# RCSS_MCASP register map
Vendor: Texas Instruments
Peripheral module from a debugger description file (folder am273).
Registers are 32-bit, read-write, no defined reset value unless marked. A register's access mark holds for its fields unless they carry their own. Offsets are as the file gives them; lines under a group give offsets from that group; [hi:lo] are bit positions; {n}, {i} and the like mark numbered series; 'fields as' and 'values as' point back to an identical list; <NAME> marks a mode.

## RCSS_MCASP (part 1 of 2)
0x00 PID ro — The revision identification register (PID) contains identification data for the peripheral.
  [31:0] ? — Identifies revision of peripheral.
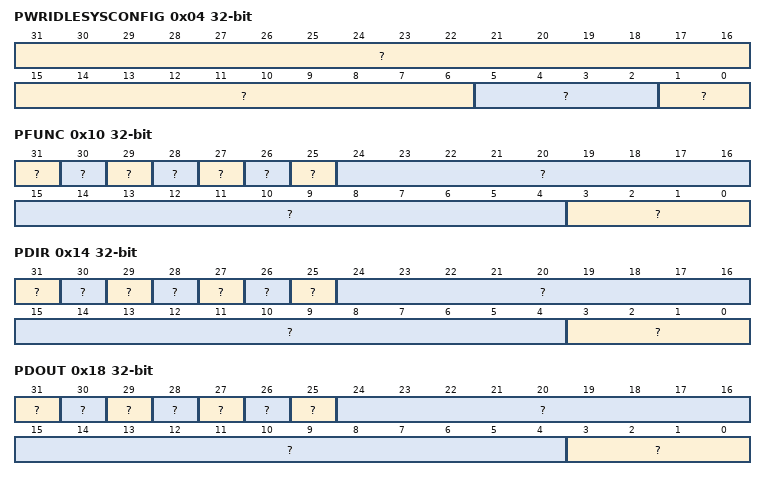
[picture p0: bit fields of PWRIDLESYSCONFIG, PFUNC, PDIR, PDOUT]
0x04 PWRIDLESYSCONFIG access per field
  [31:6] ? ro
  [5:2] ? rw — Reserved for future programming.
  [1:0] ? rw — Power management Configuration of the local target state management mode. By definition, target can handle read/write transaction as long as it is out of IDLE state.
    0=en_1_0x0 (Force-idle mode: local target's idle state follows (acknowledges) the system's idle requests unconditionally, i.e. regardless of the IP module's internal requirements. Backup mode, for debug only.); 1=en_2_0x1 (No-idle mode: local target never enters idle state. Backup mode, for debug only.); 2=en_3_0x2 (Smart-idle mode: local target's idle state eventually follows (acknowledges) the system's idle requests, depending on the IP module's internal requirements. IP module shall not generate (IRQ- or DMA-request-related) wakeup events.); 3=en_4_0x3 (Reserved.)
0x10 PFUNC access per field — The pin function register (PFUNC) specifies the function of AXRn, ACLKX, AHCLKX, AFSX, ACLKR, AHCLKR, and AFSR pins as either a McASP pin or a general-purpose input/output (GPIO) pin. CAUTION: Writing a value other than 0 to reserved bits in this register may cause improper device operation.
  [31] ? rw — Determines if AFSR pin functions as McASP or GPIO.
    0=en_1_0x0 (Pin functions as McASP pin.); 1=en_2_0x1 (Pin functions as GPIO pin.)
  [30] ? rw — Determines if AHCLKR pin functions as McASP or GPIO.
    values as ?
  [29] ? rw — Determines if ACLKR pin functions as McASP or GPIO.
    values as ?
  [28] ? rw — Determines if AFSX pin functions as McASP or GPIO.
    values as ?
  [27] ? rw — Determines if AHCLKX pin functions as McASP or GPIO.
    values as ?
  [26] ? rw — Determines if ACLKX pin functions as McASP or GPIO.
    values as ?
  [25] ? rw — Determines if AMUTE pin functions as McASP or GPIO.
    values as ?
  [24:4] ? ro
  [3:0] ? rw — Determines if AXRn pin functions as McASP or GPIO.
    values as ?
0x14 PDIR access per field — The pin direction register (PDIR) specifies the direction of AXRn, ACLKX, AHCLKX, AFSX, ACLKR, AHCLKR, and AFSR pins as either an input or an output pin. Regardless of the pin function register (PFUNC) setting, each PDIR bit must be set to 1 for the specified pin to be enabled as an output and each PDIR bit must be cleared to 0 for the specified pin to be an input. For example, if the McASP is configured to use an internally-generated bit clock and the clock is to be driven out to the system, the PFUNC bit must be cleared to 0 (McASP function) and the PDIR bit must be set to 1 (an output). When AXRn is configured to transmit, the PFUNC bit must be cleared to 0 (McASP function) and the PDIR bit must be set to 1 (an output). Similarly, when AXRn is configured to receive, the PFUNC bit must be cleared to 0 (McASP function) and the PDIR bit must be cleared to 0 (an input). CAUTION: Writing a value other than 0 to reserved bits in this register may cause improper device operation.
  [31] ? rw — Determines if AFSR pin functions as an input or output.
    0=en_1_0x0 (Pin functions as input.); 1=en_2_0x1 (Pin functions as output.)
  [30] ? rw — Determines if AHCLKR pin functions as an input or output.
    values as ?
  [29] ? rw — Determines if ACLKR pin functions as an input or output.
    values as ?
  [28] ? rw — Determines if AFSX pin functions as an input or output.
    values as ?
  [27] ? rw — Determines if AHCLKX pin functions as an input or output.
    values as ?
  [26] ? rw — Determines if ACLKX pin functions as an input or output.
    values as ?
  [25] ? rw — Determines if AMUTE pin functions as an input or output.
    values as ?
  [24:4] ? ro
  [3:0] ? rw — Determines if AXRn pin functions as an input or output.
    values as ?
0x18 PDOUT access per field — The pin data output register (PDOUT) holds a value for data out at all times, and may be read back at all times. The value held by PDOUT is not affected by writing to PDIR and PFUNC. However, the data value in PDOUT is driven out onto the McASP pin only if the corresponding bit in PFUNC is set to 1 (GPIO function) and the corresponding bit in PDIR is set to 1 (output). When reading data, returns the corresponding bit value in PDOUT[n], does not return input from I/O pin; when writing data, writes to the corresponding PDOUT[n] bit. PDOUT has these aliases or alternate addresses: PDSET When written to at this address, writing a 1 to a bit in PDSET sets the corresponding bit in PDOUT to 1; writing a 0 has no effect and keeps the bits in PDOUT unchanged. PDCLR When written to at this address, writing a 1 to a bit in PDCLR clears the corresponding bit in PDOUT to 0; writing a 0 has no effect and keeps the bits in PDOUT unchanged. There is only one set of data out bits, PDOUT[31-0]. The other registers, PDSET and PDCLR, are just different addresses for the same control bits, with different behaviors during writes. CAUTION: Writing a value other than 0 to reserved bits in this register may cause improper device operation.
  [31] ? rw — Determines drive on AFSR output pin when the corresponding PFUNC[31] and PDIR[31] bits are set to 1.
    0=en_1_0x0 (Pin drives low.); 1=en_2_0x1 (Pin drives high.)
  [30] ? rw — Determines drive on AHCLKR output pin when the corresponding PFUNC[30] and PDIR[30] bits are set to 1.
    0=en_1_0x0 (Pin drives low.); 1=en_2_0x1 (Pin drives high.)
  [29] ? rw — Determines drive on ACLKR output pin when the corresponding PFUNC[29] and PDIR[29] bits are set to 1.
    0=en_1_0x0 (Pin drives low.); 1=en_2_0x1 (Pin drives high.)
  [28] ? rw — Determines drive on AFSX output pin when the corresponding PFUNC[28] and PDIR[28] bits are set to 1.
    0=en_1_0x0 (Pin drives low.); 1=en_2_0x1 (Pin drives high.)
  [27] ? rw — Determines drive on AHCLKX output pin when the corresponding PFUNC[27] and PDIR[27] bits are set to 1.
    0=en_1_0x0 (Pin drives low.); 1=en_2_0x1 (Pin drives high.)
  [26] ? rw — Determines drive on ACLKX output pin when the corresponding PFUNC[26] and PDIR[26] bits are set to 1.
    0=en_1_0x0 (Pin drives low.); 1=en_2_0x1 (Pin drives high.)
  [25] ? rw — Determines drive on AMUTE output pin when the corresponding PFUNC[25] and PDIR[25] bits are set to 1.
    0=en_1_0x0 (Pin drives low.); 1=en_2_0x1 (Pin drives high.)
  [24:4] ? ro
  [3:0] ? rw — Determines drive on AXR[n] output pin when the corresponding PFUNC[n] and PDIR[n] bits are set to 1.
    0=en_1_0x0 (Pin drives low.); 1=en_2_0x1 (Pin drives high.)
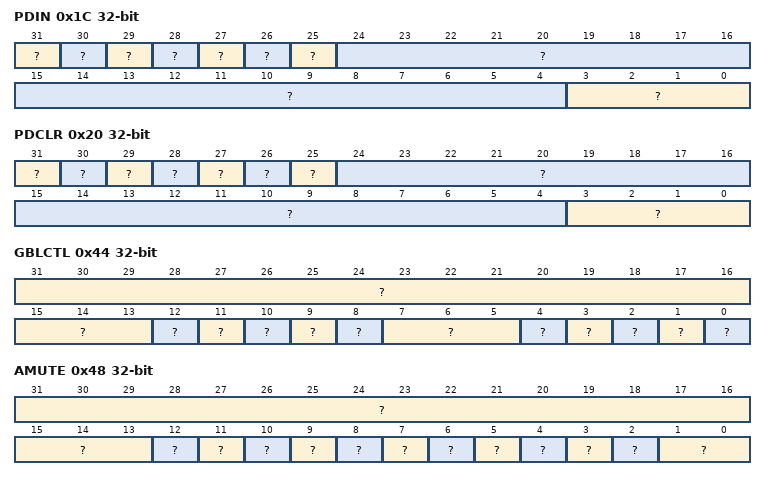
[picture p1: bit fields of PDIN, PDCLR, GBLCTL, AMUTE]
0x1C PDIN access per field — The pin data input register (PDIN) holds the I/O pin state of each of the McASP pins. PDIN allows the actual value of the pin to be read, regardless of the state of PFUNC and PDIR. The value after reset for registers 1 through 15 and 24 through 31 depends on how the pins are being driven. CAUTION: Writing a value other than 0 to reserved bits in this register may cause improper device operation.
  [31] ? rw — Logic level on AFSR pin.
    0=en_1_0x0 (Pin is logic low.); 1=en_2_0x1 (Pin is logic high.)
  [30] ? rw — Logic level on AHCLKR pin.
    values as ?
  [29] ? rw — Logic level on ACLKR pin.
    values as ?
  [28] ? rw — Logic level on AFSX pin.
    values as ?
  [27] ? rw — Logic level on AHCLKX pin.
    values as ?
  [26] ? rw — Logic level on ACLKX pin.
    values as ?
  [25] ? rw — Logic level on AMUTE pin.
    values as ?
  [24:4] ? ro
  [3:0] ? rw — Logic level on AXR[n] pin.
    values as ?
0x20 PDCLR access per field — The pin data clear register (PDCLR) is an alias of the pin data output register (PDOUT) for writes only. Writing a 1 to the PDCLR bit clears the corresponding bit in PDOUT and, if PFUNC = 1 (GPIO function) and PDIR = 1 (output), drives a logic low on the pin. PDCLR is useful for a multitasking system because it allows you to clear to a logic low only the desired pin(s) within a system without affecting other I/O pins controlled by the same McASP. CAUTION: Writing a value other than 0 to reserved bits in this register may cause improper device operation.
  [31] ? rw — Allows the corresponding AFSR bit in PDOUT to be cleared to a logic low without affecting other I/O pins controlled by the same port.
    0=en_1_0x0 (No effect.); 1=en_2_0x1 (PDOUT[31] bit is cleared to 0.)
  [30] ? rw — Allows the corresponding AHCLKR bit in PDOUT to be cleared to a logic low without affecting other I/O pins controlled by the same port.
    0=en_1_0x0 (No effect.); 1=en_2_0x1 (PDOUT[30] bit is cleared to 0.)
  [29] ? rw — Allows the corresponding ACLKR bit in PDOUT to be cleared to a logic low without affecting other I/O pins controlled by the same port.
    0=en_1_0x0 (No effect.); 1=en_2_0x1 (PDOUT[29] bit is cleared to 0.)
  [28] ? rw — Allows the corresponding AFSX bit in PDOUT to be cleared to a logic low without affecting other I/O pins controlled by the same port.
    0=en_1_0x0 (No effect.); 1=en_2_0x1 (PDOUT[28] bit is cleared to 0.)
  [27] ? rw — Allows the corresponding AHCLKX bit in PDOUT to be cleared to a logic low without affecting other I/O pins controlled by the same port.
    0=en_1_0x0 (No effect.); 1=en_2_0x1 (PDOUT[27] bit is cleared to 0.)
  [26] ? rw — Allows the corresponding ACLKX bit in PDOUT to be cleared to a logic low without affecting other I/O pins controlled by the same port.
    0=en_1_0x0 (No effect.); 1=en_2_0x1 (PDOUT[26] bit is cleared to 0.)
  [25] ? rw — Allows the corresponding AMUTE bit in PDOUT to be cleared to a logic low without affecting other I/O pins controlled by the same port.
    0=en_1_0x0 (No effect.); 1=en_2_0x1 (PDOUT[25] bit is cleared to 0.)
  [24:4] ? ro
  [3:0] ? rw — Allows the corresponding AXR[n] bit in PDOUT to be cleared to a logic low without affecting other I/O pins controlled by the same port.
    0=en_1_0x0 (No effect.); 1=en_2_0x1 (PDOUT[n] bit is cleared to 0.)
0x44 GBLCTL access per field — The global control register (GBLCTL) provides initialization of the transmit and receive sections. The bit fields in GBLCTL are synchronized and latched by the corresponding clocks (ACLKX for bits 12-8 and ACLKR for bits 4-0). Before GBLCTL is programmed, you must ensure that serial clocks are running. If the corresponding external serial clocks, ACLKX and ACLKR, are not yet running, you should select the internal serial clock source in AHCLKXCTL, AHCLKRCTL, ACLKXCTL, and ACLKRCTL before GBLCTL is programmed. Also, after programming any bits in GBLCTL you should not proceed until you have read back from GBLCTL and verified that the bits are latched in GBLCTL.
  [31:13] ? ro
  [12] ? rw — Transmit frame sync generator reset enable bit.
    0=en_1_0x0 (Transmit frame sync generator is reset.); 1=en_2_0x1 (Transmit frame sync generator is active. When released from reset, the transmit frame sync generator begins counting serial clocks and generating frame sync as programmed.)
  [11] ? rw — Transmit state machine reset enable bit.
    0=en_1_0x0 (Transmit state machine is held in reset. AXRn pin state: If PFUNC[n] = 0 and PDIR[n] = 1; then the serializer drives the AXRn pin to the state specified for inactive time slot (as determined by DISMOD bits in SRCTL).); 1=en_2_0x1 (Transmit state machine is released from reset. When released from reset, the transmit state machine immediately transfers data from XRBUF[n] to XRSR[n]. The transmit state machine sets the underrun flag (XUNDRN) in XSTAT, if XRBUF[n] have not been preloaded with data before reset is released. The transmit state machine also immediately begins detecting frame sync and is ready to transmit. Transmit TDM time slot begins at slot 0 after reset is released.)
  [10] ? rw — Transmit serializer clear enable bit. By clearing then setting this bit, the transmit buffer is flushed to an empty state [XDATA = 1]. If XSMRST = 1, XSRCLR = 1, XDATA = 1, and XBUF is not loaded with new data before the start of the next active time slot, an underrun will occur.
    0=en_1_0x0 (Transmit serializers are cleared.); 1=en_2_0x1 (Transmit serializers are active. When the transmit serializers are first taken out of reset (XSRCLR changes from 0 to 1), the transmit data ready bit (XDATA) in XSTAT is set to indicate XBUF is ready to be written.)
  [9] ? rw — Transmit high-frequency clock divider reset enable bit.
    0=en_1_0x0 (Transmit high-frequency clock divider is held in reset and passes through its input as divide-by-1.); 1=en_2_0x1 (Transmit high-frequency clock divider is running.)
  [8] ? rw — Transmit clock divider reset enable bit.
    0=en_1_0x0 (Transmit clock divider is held in reset. When the clock divider is in reset, it passes through a divide-by-1 of its input.); 1=en_2_0x1 (Transmit clock divider is running.)
  [7:5] ? ro
  [4] ? rw — Receive frame sync generator reset enable bit.
    0=en_1_0x0 (Receive frame sync generator is reset.); 1=en_2_0x1 (Receive frame sync generator is active. When released from reset, the receive frame sync generator begins counting serial clocks and generating frame sync as programmed.)
  [3] ? rw — Receive state machine reset enable bit.
    0=en_1_0x0 (Receive state machine is held in reset.); 1=en_2_0x1 (Receive state machine is released from reset. When released from reset, the receive state machine immediately begins detecting frame sync and is ready to receive. Receive TDM time slot begins at slot 0 after reset is released.)
  [2] ? rw — Receive serializer clear enable bit. By clearing then setting this bit, the receive buffer is flushed.
    0=en_1_0x0 (Receive serializers are cleared.); 1=en_2_0x1 (Receive serializers are active.)
  [1] ? rw — Receive high-frequency clock divider reset enable bit.
    0=en_1_0x0 (Receive high-frequency clock divider is held in reset and passes through its input as divide-by-1.); 1=en_2_0x1 (Receive high-frequency clock divider is running.)
  [0] ? rw — Receive high-frequency clock divider reset enable bit.
    0=en_1_0x0 (Receive clock divider is held in reset. When the clock divider is in reset, it passes through a divide-by-1 of its input.); 1=en_2_0x1 (Receive clock divider is running.)
0x48 AMUTE access per field — The audio mute control register (AMUTE) controls the McASP audio mute (AMUTE) output pin. The value after reset for register 4 depends on how the pins are being driven.
  [31:13] ? ro
  [12] ? rw — If transmit DMA error [XDMAERR], drive AMUTE active enable bit.
    0=en_1_0x0 (Drive is disabled. Detection of transmit DMA error is ignored by AMUTE.); 1=en_2_0x1 (Drive is enabled (active). Upon detection of transmit DMA error, AMUTE is active and is driven according to MUTEN bit.)
  [11] ? rw — If receive DMA error [RDMAERR], drive AMUTE active enable bit.
    0=en_1_0x0 (Drive is disabled. Detection of receive DMA error is ignored by AMUTE.); 1=en_2_0x1 (Drive is enabled (active). Upon detection of receive DMA error, AMUTE is active and is driven according to MUTEN bit.)
  [10] ? rw — If transmit clock failure [XCKFAIL], drive AMUTE active enable bit.
    0=en_1_0x0 (Drive is disabled. Detection of transmit clock failure is ignored by AMUTE.); 1=en_2_0x1 (Drive is enabled (active). Upon detection of transmit clock failure, AMUTE is active and is driven according to MUTEN bit)
  [9] ? rw — If receive clock failure [RCKFAIL], drive AMUTE active enable bit.
    0=en_1_0x0 (Drive is disabled. Detection of receive clock failure is ignored by AMUTE.); 1=en_2_0x1 (Drive is enabled (active). Upon detection of receive clock failure, AMUTE is active and is driven according to MUTEN bit.)
  [8] ? rw — If unexpected transmit frame sync error [XSYNCERR], drive AMUTE active enable bit.
    0=en_1_0x0 (Drive is disabled. Detection of unexpected transmit frame sync error is ignored by AMUTE.); 1=en_2_0x1 (Drive is enabled (active). Upon detection of unexpected transmit frame sync error, AMUTE is active and is driven according to MUTEN bit.)
  [7] ? rw — If unexpected receive frame sync error [RSYNCERR], drive AMUTE active enable bit.
    0=en_1_0x0 (Drive is disabled. Detection of unexpected receive frame sync error is ignored by AMUTE.); 1=en_2_0x1 (Drive is enabled (active). Upon detection of unexpected receive frame sync error, AMUTE is active and is driven according to MUTEN bit.)
  [6] ? rw — If transmit underrun error [XUNDRN], drive AMUTE active enable bit.
    0=en_1_0x0 (Drive is disabled. Detection of transmit underrun error is ignored by AMUTE.); 1=en_2_0x1 (Drive is enabled (active). Upon detection of transmit underrun error, AMUTE is active and is driven according to MUTEN bit.)
  [5] ? rw — If receiver overrun error [ROVRN], drive AMUTE active enable bit.
    0=en_1_0x0 (Drive is disabled. Detection of receiver overrun error is ignored by AMUTE.); 1=en_2_0x1 (Drive is enabled (active). Upon detection of receiver overrun error, AMUTE is active and is driven according to MUTEN bit.)
  [4] ? ro — Determines drive on AXRn pin when PFUNC[n] and PDIR[n] bits are set to 1.
    0=en_1_0x0 (AMUTEIN pin is inactive.); 1=en_2_0x1 (AMUTEIN pin is active. Audio mute in error is detected.)
  [3] ? rw — Drive AMUTE active when AMUTEIN error is active [INSTAT = 1].
    0=en_1_0x0 (Drive is disabled. AMUTEIN is ignored by AMUTE.); 1=en_2_0x1 (Drive is enabled (active). INSTAT = 1 drives AMUTE active.)
  [2] ? rw — Audio mute in [AMUTEIN] polarity select bit.
    0=en_1_0x0 (Polarity is active high. A high on AMUTEIN sets INSTAT to 1.); 1=en_2_0x1 (Polarity is active low. A low on AM UTEIN sets INSTAT to 1.)
  [1:0] ? rw — AMUTE pin enable bit [unless overridden by GPIO registers].
    0=en_1_0x0 (AMUTE pin is disabled, pin goes to tri-state condition.); 1=en_2_0x1 (AMUTE pin is driven high if error is detected.); 2=en_3_0x2 (AMUTE pin is driven low if error is detected.); 3=en_4_0x3 (Reserved)
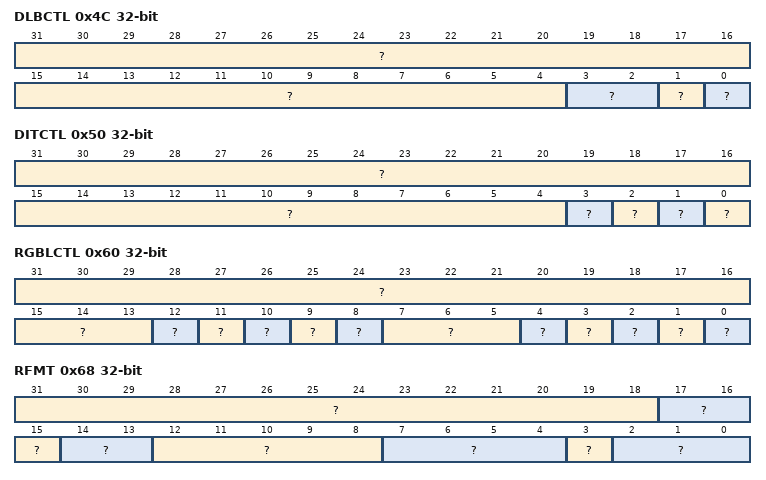
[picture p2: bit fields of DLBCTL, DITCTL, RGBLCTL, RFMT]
0x4C DLBCTL access per field — The digital loopback control register (DLBCTL) controls the internal loopback settings of the McASP in TDM mode.
  [31:4] ? ro
  [3:2] ? rw — Loopback generator mode bits. Applies only when loopback mode is enabled [DLBEN = 1].
    0=en_1_0x0 (Default and reserved on loopback mode (DLBEN = 1). When in non-loopback mode (DLBEN = 0), MODE should be left at default (00). When in loopback mode (DLBEN = 1), MODE = 00 is reserved and is not applicable.); 1=en_2_0x1 (Transmit clock and frame sync generators used by both transmit and receive sections. When in loopback mode (DLBEN = 1), MODE must be 01.); 2=en_3_0x2 (Reserved.); 3=en_4_0x3 (Reserved.)
  [1] ? rw — Loopback order bit when loopback mode is enabled [DLBEN = 1].
    0=en_1_0x0 (Odd serializers N + 1 transmit to even serializers N that receive. The corresponding serializers must be programmed properly.); 1=en_2_0x1 (Even serializers N transmit to odd serializers N + 1 that receive. The corresponding serializers must be programmed properly.)
  [0] ? rw — Loopback mode enable bit.
    0=en_1_0x0 (Loopback mode is disabled.); 1=en_2_0x1 (Loopback mode is enabled.)
0x50 DITCTL access per field — The DIT mode control register (DITCTL) controls DIT operations of the McASP.
  [31:4] ? ro
  [3] ? rw — Valid bit for odd time slots [DIT right subframe].
    0=en_1_0x0 (V bit is 0 during odd DIT subframes.); 1=en_2_0x1 (V bit is 1 during odd DIT subframes.)
  [2] ? rw — Valid bit for even time slots [DIT left subframe].
    0=en_1_0x0 (V bit is 0 during even DIT subframes.); 1=en_2_0x1 (V bit is 1 during even DIT subframes.)
  [1] ? ro
  [0] ? rw — DIT mode enable bit. DITEN should only be changed while the XSMRST bit in GBLCTL is in reset [and for startup, XSRCLR also in reset]. However, it is not necessary to reset the XCLKRST or XHCLKRST bits in GBLCTL to change DITEN.
    0=en_1_0x0 (DIT mode is disabled. Transmitter operates in TDM or burst mode.); 1=en_2_0x1 (DIT mode is enabled. Transmitter operates in DIT encoded mode.)
0x60 RGBLCTL access per field — Alias of the global control register (GBLCTL). Writing to the receiver global control register (RGBLCTL) affects only the receive bits of GBLCTL (bits 4-0). Reads from RGBLCTL return the value of GBLCTL. RGBLCTL allows the receiver to be reset independently from the transmitter.
  [31:13] ? ro
  [12] ? ro — Transmit frame sync generator reset enable bit. A read of this bit returns the XFRST bit value of GBLCTL. Writes have no effect.
  [11] ? ro — Transmit state machine reset enable bit. A read of this bit returns the XSMRST bit value of GBLCTL. Writes have no effect.
  [10] ? ro — Transmit serializer clear enable bit. A read of this bit returns the XSRCLR bit value of GBLCTL. Writes have no effect.
  [9] ? ro — Transmit high-frequency clock divider reset enable bit. A read of this bit returns the XHCLKRST bit value of GBLCTL. Writes have no effect.
  [8] ? ro — Transmit clock divider reset enable bit. A read of this bit returns the XCLKRST bit value of GBLCTL. Writes have no effect.
  [7:5] ? ro
  [4] ? rw — Receive frame sync generator reset enable bit. A write to this bit affects the RFRST bit of GBLCTL.
    0=en_1_0x0 (Receive frame sync generator is reset.); 1=en_2_0x1 (Receive frame sync generator is active.)
  [3] ? rw — Receive state machine reset enable bit. A write to this bit affects the RSMRST bit of GBLCTL.
    0=en_1_0x0 (Receive state machine is held in reset.); 1=en_2_0x1 (Receive state machine is released from reset.)
  [2] ? rw — Receive serializer clear enable bit. A write to this bit affects the RSRCLR bit of GBLCTL.
    0=en_1_0x0 (Receive serializers are cleared.); 1=en_2_0x1 (Receive serializers are active.)
  [1] ? rw — Receive high-frequency clock divider reset enable bit. A write to this bit affects the RHCLKRST bit of GBLCTL.
    0=en_1_0x0 (Receive high-frequency clock divider is held in reset and passes through its input as divide-by-1.); 1=en_2_0x1 (Receive high-frequency clock divider is running.)
  [0] ? rw — Receive clock divider reset enable bit. A write to this bit affects the RCLKRST bit of GBLCTL.
    0=en_1_0x0 (Receive clock divider is held in reset.); 1=en_2_0x1 (Receive clock divider is running.)
0x64 RMASK — The receive format unit bit mask register (RMASK) determines which bits of the received data are masked off and padded with a known value before being read by the CPU or DMA.
  [31:0] ? — Receive data mask n enable bit.
    0=en_1_0x0 (Corresponding bit of receive data (after passing through reverse and rotate units) is masked out and then padded with the selected bit pad value (RPAD and RPBIT bits in RFMT).); 1=en_2_0x1 (Corresponding bit of receive data (after passing through reverse and rotate units) is returned to CPU or DMA.)
0x68 RFMT access per field — The receive bit stream format register (RFMT) configures the receive data format.
  [31:18] ? ro
  [17:16] ? rw — Receive bit delay.
    0=en_1_0x0 (0-bit delay. The first receive data bit, AXRn, occurs in same ACLKR cycle as the receive frame sync (AFSR).); 1=en_2_0x1 (1-bit delay. The first receive data bit, AXRn, occurs one ACLKR cycle after the receive frame sync (AFSR).); 2=en_3_0x2 (2-bit delay. The first receive data bit, AXRn, occurs two ACLKR cycles after the receive frame sync (AFSR).); 3=en_4_0x3 (Reserved.)
  [15] ? rw — Receive serial bitstream order.
    0=en_1_0x0 (Bitstream is LSB first. No bit reversal is performed in receive format bit reverse unit.); 1=en_2_0x1 (Bitstream is MSB first. Bit reversal is performed in receive format bit reverse unit.)
  [14:13] ? rw — Pad value for extra bits in slot not belonging to the word. This field only applies to bits when RMASK[n] = 0.
    0=en_1_0x0 (Pad extra bits with 0.); 1=en_2_0x1 (Pad extra bits with 1.); 2=en_3_0x2 (Pad extra bits with one of the bits from the word as specified by RPBIT bits.); 3=en_4_0x3 (Reserved.)
  [12:8] ? rw — RPBIT value determines which bit [as read by the CPU or DMA from RBUF[n]] is used to pad the extra bits. This field only applies when RPAD = 2h.
    0=en_1_0x0 (Pad with bit 0 value.); 1=en_2_0x1 (Pad with bit 1 to bit 31 value from 1h to 1Fh.)
  [7:4] ? rw — Receive slot size.
    0=en_7_0x0 (Reseved.); 1=en_8_0x1 (Reserved.); 2=en_9_0x2 (Reserved.); 3=en_10_0x3 (Slot size is 8 bits.); 4=en_11_0x4 (Reserved); 5=en_12_0x5 (Slot size is 12 bits.); 6=en_13_0x6 (Reserved); 7=en_14_0x7 (Slot size is 16 bits.); 8=en_15_0x8 (Reserved); 9=en_16_0x9 (Slot size is 20 bits.); 10=en_5_0xA (Reserved); 11=en_1_0xB (Slot size is 24 bits); 12=en_4_0xC (Reserved); 13=en_2_0xD (Slot size is 28 bits.); 14=en_6_0xE (Reserved); 15=en_3_0xF (Slot size is 32 bits.)
  [3] ? rw — Selects whether reads from serializer buffer XRBUF[n] originate from the configuration bus [CFG] or the data [DAT] port.
    0=en_1_0x0 (Reads from XRBUF[n] originate on data port. Reads from XRBUF[n] on configuration bus are ignored.); 1=en_2_0x1 (Reads from XRBUF[n] originate on configuration bus. Reads from XRBUF[n] on data port are ignored.)
  [2:0] ? rw — Right-rotation value for receive rotate right format unit.
    0=en_1_0x0 (Rotate right by 0 (no rotation).); 1=en_2_0x1 (Rotate right by 4 bit positions.); 2=en_3_0x2 (Rotate right by 8 bit positions.); 3=en_4_0x3 (Rotate right by 12 bit positions.); 4=en_5_0x4 (Rotate right by 16 bit positions.); 5=en_6_0x5 (Rotate right by 20 bit positions.); 6=en_7_0x6 (Rotate right by 24 bit positions.); 7=en_8_0x7 (Rotate right by 28 bit positions.)
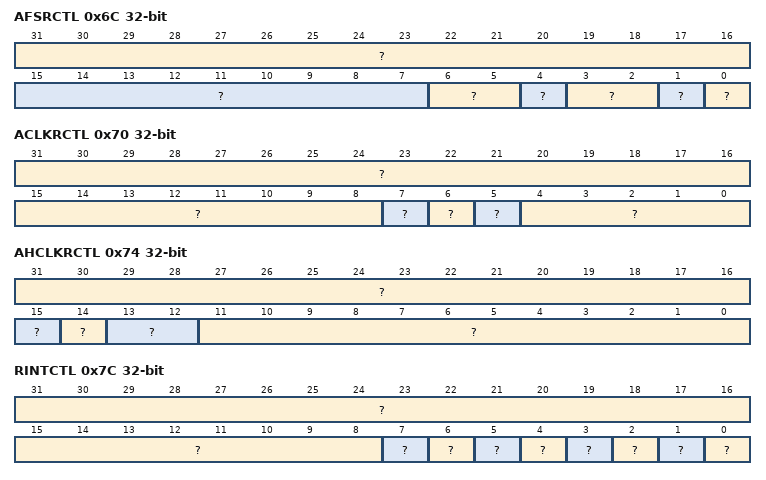
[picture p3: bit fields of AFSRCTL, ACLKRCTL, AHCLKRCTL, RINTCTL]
0x6C AFSRCTL access per field — The receive frame sync control register (AFSRCTL) configures the receive frame sync (AFSR).
  [31:16] ? ro
  [15:7] ? rw — Receive frame sync mode select bits. 1FFh = Reserved from 181h to 1FFh.
    0=en_1_0x0 (Burst mode.); 1=en_2_0x1 (Reserved.); 2=en_3_0x2 (2-slot TDM (I2S mode) to 32-slot TDM from 2h to 20h.); 33=en_4_0x21 (Reserved from 21h to 17Fh.); 0x180=en_5_0x180 (384-slot TDM (external DIR IC inputting 384-slot DIR frames to McASP over I2S interface).); 0x181=en_6_0x181 (Reserved from 181h to 1FFh.)
  [6:5] ? ro
  [4] ? rw — Receive frame sync width select bit indicates the width of the receive frame sync [AFSR] during its active period.
    0=en_1_0x0 (Single bit.); 1=en_2_0x1 (Single word.)
  [3:2] ? ro
  [1] ? rw — Receive frame sync generation select bit.
    0=en_1_0x0 (Externally-generated receive frame sync.); 1=en_2_0x1 (Internally-generated receive frame sync.)
  [0] ? rw — Receive frame sync polarity select bit.
    0=en_1_0x0 (A rising edge on receive frame sync (AFSR) indicates the beginning of a frame.); 1=en_2_0x1 (A falling edge on receive frame sync (AFSR) indicates the beginning of a frame.)
0x70 ACLKRCTL access per field — The receive clock control register (ACLKRCTL) configures the receive bit clock (ACLKR) and the receive clock generator.
  [31:8] ? ro
  [7] ? rw — Receive bitstream clock polarity select bit.
    0=en_1_0x0 (Falling edge. Receiver samples data on the falling edge of the serial clock, so the external transmitter driving this receiver must shift data out on the rising edge of the serial clock.); 1=en_2_0x1 (Rising edge. Receiver samples data on the rising edge of the serial clock, so the external transmitter driving this receiver must shift data out on the falling edge of the serial clock.)
  [6] ? ro
  [5] ? rw — Receive bit clock source bit. Note that this bit does not have any effect, if ACLKXCTL.ASYNC = 0.
    0=en_1_0x0 (External receive clock source from ACLKR pin.); 1=en_2_0x1 (Internal receive clock source from output of programmable bit clock divider.)
  [4:0] ? rw — Receive bit clock divide ratio bits determine the divide-down ratio from AHCLKR to ACLKR. Note that this bit does not have any effect, if ACLKXCTL.ASYNC = 0.
    0=en_1_0x0 (Divide-by-1.); 1=en_2_0x1 (Divide-by-2.); 2=en_3_0x2 (Divide-by-3 to divide-by-32 from 2h to 1Fh.)
0x74 AHCLKRCTL access per field — The receive high-frequency clock control register (AHCLKRCTL) configures the receive high-frequency master clock (AHCLKR) and the receive clock generator.
  [31:16] ? ro
  [15] ? rw — Receive high-frequency clock source bit.
    0=en_1_0x0 (External receive high-frequency clock source from AHCLKR pin.); 1=en_2_0x1 (Internal receive high-frequency clock source from output of programmable high clock divider.)
  [14] ? rw — Receive bitstream high-frequency clock polarity select bit.
    0=en_1_0x0 (AHCLKR is not inverted before programmable bit clock divider. In the special case where the receive bit clock (ACLKR) is internally generated and the programmable bit clock divider is set to divide-by-1 (CLKRDIV = 0 in ACLKRCTL), AHCLKR is directly passed through to the ACLKR pin.); 1=en_2_0x1 (AHCLKR is inverted before programmable bit clock divider. In the special case where the receive bit clock (ACLKR) is internally generated and the programmable bit clock divider is set to divide-by-1 (CLKRDIV = 0 in ACLKRCTL), AHCLKR is directly passed through to the ACLKR pin.)
  [13:12] ? ro
  [11:0] ? rw — Receive high-frequency clock divide ratio bits determine the divide-down ratio from AUXCLK to AHCLKR.
    0=en_1_0x0 (Divide-by-1.); 1=en_2_0x1 (Divide-by-2.); 2=en_3_0x2 (Divide-by-3 to divide-by-4096 from 2h to FFFh.)
0x78 RTDM — The receive TDM time slot register (RTDM) specifies which TDM time slot the receiver is active.
  [31:0] ? — Receiver mode during TDM time slot n.
    0=en_1_0x0 (Receive TDM time slot n is inactive. The receive serializer does not shift in data during this slot.); 1=en_2_0x1 (Receive TDM time slot n is active. The receive serializer shifts in data during this slot.)
0x7C RINTCTL access per field — The receiver interrupt control register (RINTCTL) controls generation of the McASP receive interrupt (RINT). When the register bit(s) is set to 1, the occurrence of the enabled McASP condition(s) generates RINT. See the RSTAT register for a description of the interrupt conditions.
  [31:8] ? ro
  [7] ? rw — Receive start of frame interrupt enable bit.
    0=en_1_0x0 (Interrupt is disabled. A receive start of frame interrupt does not generate a McASP receive interrupt (RINT).); 1=en_2_0x1 (Interrupt is enabled. A receive start of frame interrupt generates a McASP receive interrupt (RINT).)
  [6] ? ro
  [5] ? rw — Receive data ready interrupt enable bit.
    0=en_1_0x0 (Interrupt is disabled. A receive data ready interrupt does not generate a McASP receive interrupt (RINT).); 1=en_2_0x1 (Interrupt is enabled. A receive data ready interrupt generates a McASP receive interrupt (RINT).)
  [4] ? rw — Receive last slot interrupt enable bit.
    0=en_1_0x0 (Interrupt is disabled. A receive last slot interrupt does not generate a McASP receive interrupt (RINT).); 1=en_2_0x1 (Interrupt is enabled. A receive last slot interrupt generates a McASP receive interrupt (RINT).)
  [3] ? rw — Receive DMA error interrupt enable bit.
    0=en_1_0x0 (Interrupt is disabled. A receive DMA error interrupt does not generate a McASP receive interrupt (RINT).); 1=en_2_0x1 (Interrupt is enabled. A receive DMA error interrupt generates a McASP receive interrupt (RINT).)
  [2] ? rw — Receive clock failure interrupt enable bit.
    0=en_1_0x0 (Interrupt is disabled. A receive clock failure interrupt does not generate a McASP receive interrupt (RINT).); 1=en_2_0x1 (Interrupt is enabled. A receive clock failure interrupt generates a McASP receive interrupt (RINT).)
  [1] ? rw — Unexpected receive frame sync interrupt enable bit.
    0=en_1_0x0 (Interrupt is disabled. An unexpected receive frame sync interrupt does not generate a McASP receive interrupt (RINT).); 1=en_2_0x1 (Interrupt is enabled. An unexpected receive frame sync interrupt generates a McASP receive interrupt (RINT).)
  [0] ? rw — Receiver overrun interrupt enable bit.
    0=en_1_0x0 (Interrupt is disabled. A receiver overrun interrupt does not generate a McASP receive interrupt (RINT).); 1=en_2_0x1 (Interrupt is enabled. A receiver overrun interrupt generates a McASP receive interrupt (RINT).)
